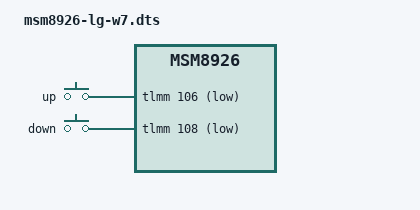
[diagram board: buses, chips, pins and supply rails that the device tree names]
// SPDX-License-Identifier: BSD-3-Clause

#include <skeleton32.dtsi>
#include <lk2nd.dtsi>

/ {
	qcom,msm-id = <0x91 0x20000 0x9e 0x20000 0x9f 0x20000 0xc6 0x20000 0xcd 0x20000 0xdc 0x20000 0xdd 0x20000 0xde 0x20000 0xdf 0x20000>;
	qcom,board-id = <101 0>;
};

&lk2nd {
	model = "LG L90";
	compatible = "lg,w7";

	lk2nd,dtb-files = "msm8926-lge-w7";

	gpio-keys {
		compatible = "gpio-keys";
		up {
			lk2nd,code = <KEY_VOLUMEUP>;
			gpios = <&tlmm 106 (GPIO_ACTIVE_LOW | GPIO_PULL_UP)>;
		};
		down {
			lk2nd,code = <KEY_VOLUMEDOWN>;
			gpios = <&tlmm 108 (GPIO_ACTIVE_LOW | GPIO_PULL_UP)>;
		};
	};
};
